# CC3200 register map
Vendor: Texas Instruments; Series: SimpleLink; File version: 1.0
CPU: CM4 r0p1, little endian, MPU, no FPU, 3 interrupt priority bits
Registers are 32-bit, read-write, reset 0x0 unless marked. A register's access mark holds for its fields unless they carry their own. Offsets are from the block's base; [hi:lo] are bit positions; 'fields as' and 'values as' point back to an identical list.

## UART — UARTA0
Base 0x4000C000
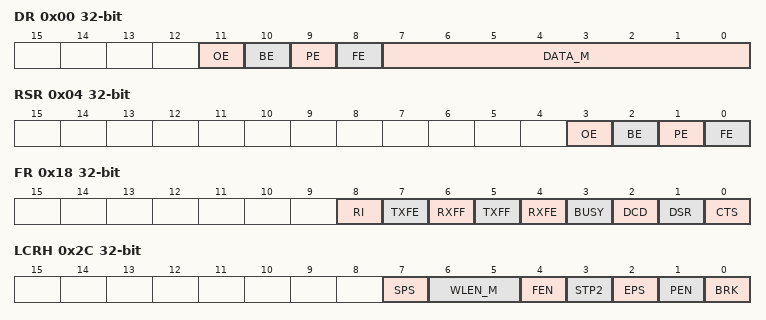
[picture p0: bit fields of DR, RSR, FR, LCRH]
0x00 DR — UART_DR
  [11] OE — UART_DR
  [10] BE — UART_DR
  [9] PE — UART_DR
  [8] FE — UART_DR
  [7:0] DATA_M — UART_DR
0x04 RSR — UART_RSR
  [3] OE — UART_RSR
  [2] BE — UART_RSR
  [1] PE — UART_RSR
  [0] FE — UART_RSR
0x04 ECR — UART_ECR
  [7:0] DATA_M
0x18 FR — UART_FR
  [8] RI — UART_FR
  [7] TXFE — UART_FR
  [6] RXFF — UART_FR
  [5] TXFF — UART_FR
  [4] RXFE — UART_FR
  [3] BUSY — UART_FR
  [2] DCD — UART_FR
  [1] DSR — UART_FR
  [0] CTS — UART_FR
0x20 ILPR — UART_ILPR
  [7:0] ILPDVSR_M
0x24 IBRD — UART_IBRD
  [15:0] DIVINT_M
0x28 FBRD — UART_FBRD
  [5:0] DIVFRAC_M
0x2C LCRH — UART_LCRH
  [7] SPS — UART_LCRH
  [6:5] WLEN_M — UART_LCRH
  [4] FEN — UART_LCRH
  [3] STP2 — UART_LCRH
  [2] EPS — UART_LCRH
  [1] PEN — UART_LCRH
  [0] BRK — UART_LCRH
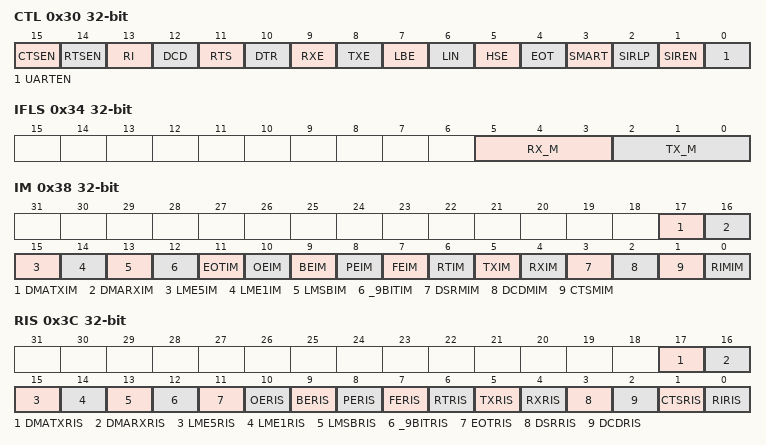
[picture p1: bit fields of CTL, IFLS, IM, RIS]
0x30 CTL — UART_CTL
  [15] CTSEN — UART_CTL
  [14] RTSEN — UART_CTL
  [13] RI — UART_CTL
  [12] DCD — UART_CTL
  [11] RTS — UART_CTL
  [10] DTR — UART_CTL
  [9] RXE — UART_CTL
  [8] TXE — UART_CTL
  [7] LBE — UART_CTL
  [6] LIN — UART_CTL
  [5] HSE — UART_CTL
  [4] EOT — UART_CTL
  [3] SMART — UART_CTL
  [2] SIRLP — UART_CTL
  [1] SIREN — UART_CTL
  [0] UARTEN — UART_CTL
0x34 IFLS — UART_IFLS
  [5:3] RX_M — UART_IFLS
  [2:0] TX_M — UART_IFLS
0x38 IM — UART_IM
  [17] DMATXIM — UART_IM
  [16] DMARXIM — UART_IM
  [15] LME5IM — UART_IM
  [14] LME1IM — UART_IM
  [13] LMSBIM — UART_IM
  [12] _9BITIM — UART_IM
  [11] EOTIM — UART_IM
  [10] OEIM — UART_IM
  [9] BEIM — UART_IM
  [8] PEIM — UART_IM
  [7] FEIM — UART_IM
  [6] RTIM — UART_IM
  [5] TXIM — UART_IM
  [4] RXIM — UART_IM
  [3] DSRMIM — UART_IM
  [2] DCDMIM — UART_IM
  [1] CTSMIM — UART_IM
  [0] RIMIM — UART_IM
0x3C RIS — UART_RIS
  [17] DMATXRIS — UART_RIS
  [16] DMARXRIS — UART_RIS
  [15] LME5RIS — UART_RIS
  [14] LME1RIS — UART_RIS
  [13] LMSBRIS — UART_RIS
  [12] _9BITRIS — UART_RIS
  [11] EOTRIS — UART_RIS
  [10] OERIS — UART_RIS
  [9] BERIS — UART_RIS
  [8] PERIS — UART_RIS
  [7] FERIS — UART_RIS
  [6] RTRIS — UART_RIS
  [5] TXRIS — UART_RIS
  [4] RXRIS — UART_RIS
  [3] DSRRIS — UART_RIS
  [2] DCDRIS — UART_RIS
  [1] CTSRIS — UART_RIS
  [0] RIRIS — UART_RIS
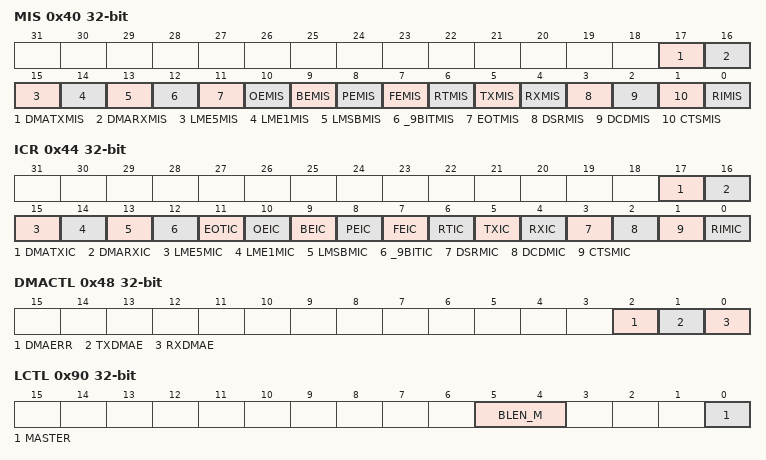
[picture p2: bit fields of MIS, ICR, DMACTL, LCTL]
0x40 MIS — UART_MIS
  [17] DMATXMIS — UART_MIS
  [16] DMARXMIS — UART_MIS
  [15] LME5MIS — UART_MIS
  [14] LME1MIS — UART_MIS
  [13] LMSBMIS — UART_MIS
  [12] _9BITMIS — UART_MIS
  [11] EOTMIS — UART_MIS
  [10] OEMIS — UART_MIS
  [9] BEMIS — UART_MIS
  [8] PEMIS — UART_MIS
  [7] FEMIS — UART_MIS
  [6] RTMIS — UART_MIS
  [5] TXMIS — UART_MIS
  [4] RXMIS — UART_MIS
  [3] DSRMIS — UART_MIS
  [2] DCDMIS — UART_MIS
  [1] CTSMIS — UART_MIS
  [0] RIMIS — UART_MIS
0x44 ICR — UART_ICR
  [17] DMATXIC — UART_ICR
  [16] DMARXIC — UART_ICR
  [15] LME5MIC — UART_ICR
  [14] LME1MIC — UART_ICR
  [13] LMSBMIC — UART_ICR
  [12] _9BITIC — UART_ICR
  [11] EOTIC — UART_ICR
  [10] OEIC — UART_ICR
  [9] BEIC — UART_ICR
  [8] PEIC — UART_ICR
  [7] FEIC — UART_ICR
  [6] RTIC — UART_ICR
  [5] TXIC — UART_ICR
  [4] RXIC — UART_ICR
  [3] DSRMIC — UART_ICR
  [2] DCDMIC — UART_ICR
  [1] CTSMIC — UART_ICR
  [0] RIMIC — UART_ICR
0x48 DMACTL — UART_DMACTL
  [2] DMAERR — UART_DMACTL
  [1] TXDMAE — UART_DMACTL
  [0] RXDMAE — UART_DMACTL
0x90 LCTL — UART_LCTL
  [5:4] BLEN_M — UART_LCTL
  [0] MASTER — UART_LCTL
0x94 LSS — UART_LSS
  [15:0] TSS_M
0x98 LTIM — UART_LTIM
  [15:0] TIMER_M
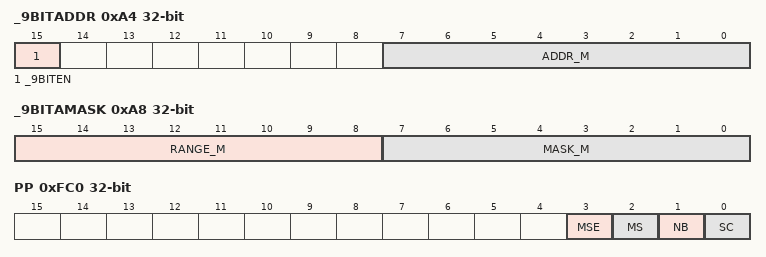
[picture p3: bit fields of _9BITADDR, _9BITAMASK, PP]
0xA4 _9BITADDR — UART_9BITADDR
  [15] _9BITEN — UART_9BITADDR
  [7:0] ADDR_M — UART_9BITADDR
0xA8 _9BITAMASK — UART_9BITAMASK
  [15:8] RANGE_M — UART_9BITAMASK
  [7:0] MASK_M — UART_9BITAMASK
0xFC0 PP — UART_PP
  [3] MSE — UART_PP
  [2] MS — UART_PP
  [1] NB — UART_PP
  [0] SC — UART_PP
0xFC8 CC — UART_CC
  [3:0] CS_M

## UART — UARTA1
Base 0x4000D000
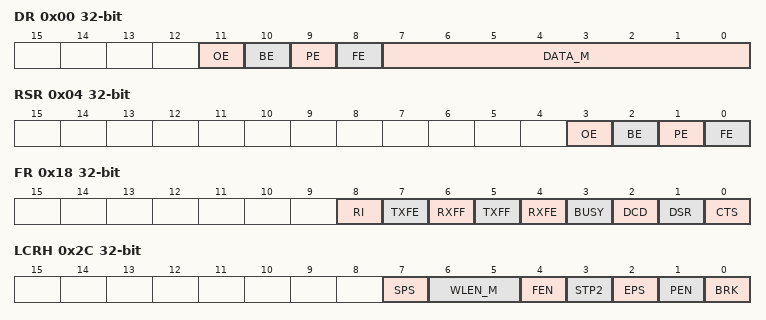
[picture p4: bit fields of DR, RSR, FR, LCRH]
0x00 DR — UART_DR
  fields as DR
0x04 RSR — UART_RSR
  fields as RSR
0x04 ECR — UART_ECR
  [7:0] DATA_M
0x18 FR — UART_FR
  fields as FR
0x20 ILPR — UART_ILPR
  [7:0] ILPDVSR_M
0x24 IBRD — UART_IBRD
  [15:0] DIVINT_M
0x28 FBRD — UART_FBRD
  [5:0] DIVFRAC_M
0x2C LCRH — UART_LCRH
  fields as LCRH
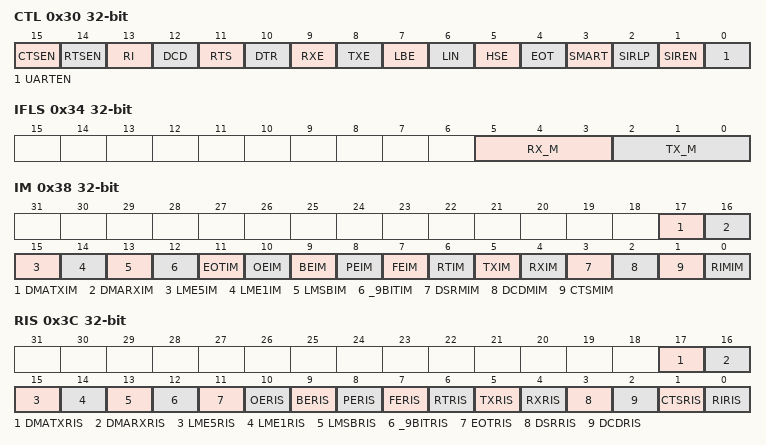
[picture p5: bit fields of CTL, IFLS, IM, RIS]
0x30 CTL — UART_CTL
  fields as CTL
0x34 IFLS — UART_IFLS
  [5:3] RX_M — UART_IFLS
  [2:0] TX_M — UART_IFLS
0x38 IM — UART_IM
  fields as IM
0x3C RIS — UART_RIS
  fields as RIS
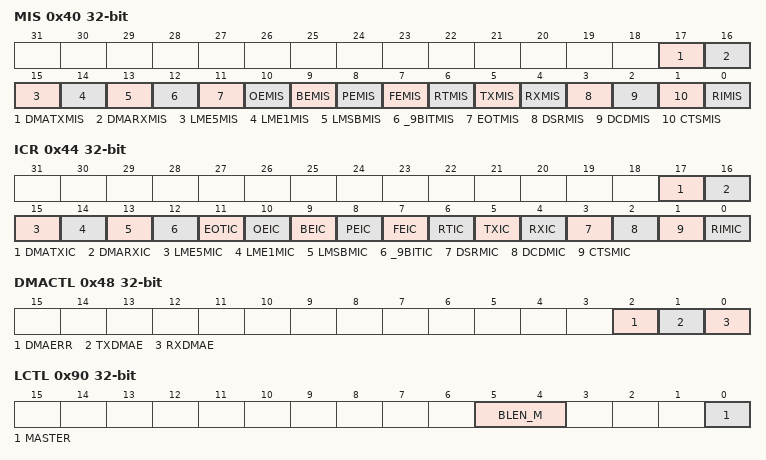
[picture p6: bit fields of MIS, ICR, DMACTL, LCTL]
0x40 MIS — UART_MIS
  fields as MIS
0x44 ICR — UART_ICR
  fields as ICR
0x48 DMACTL — UART_DMACTL
  fields as DMACTL
0x90 LCTL — UART_LCTL
  [5:4] BLEN_M — UART_LCTL
  [0] MASTER — UART_LCTL
0x94 LSS — UART_LSS
  [15:0] TSS_M
0x98 LTIM — UART_LTIM
  [15:0] TIMER_M
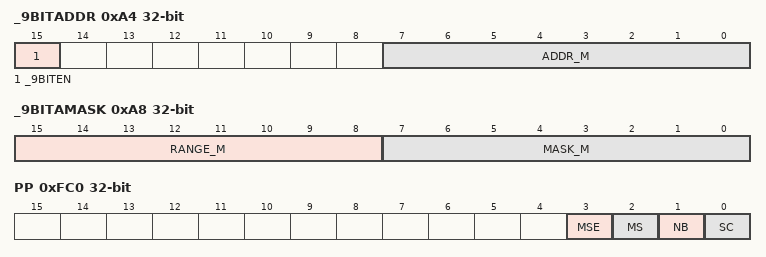
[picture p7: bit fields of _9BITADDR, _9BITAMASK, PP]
0xA4 _9BITADDR — UART_9BITADDR
  [15] _9BITEN — UART_9BITADDR
  [7:0] ADDR_M — UART_9BITADDR
0xA8 _9BITAMASK — UART_9BITAMASK
  [15:8] RANGE_M — UART_9BITAMASK
  [7:0] MASK_M — UART_9BITAMASK
0xFC0 PP — UART_PP
  fields as PP
0xFC8 CC — UART_CC
  [3:0] CS_M
